# CTRL_MMR0_CTRL_MMR0_IP_CTRL_MMRS_09180000h register map
Vendor: Texas Instruments
Peripheral module from a debugger description file (folder am62L).
Registers are 32-bit, read-write, reset 0x0 unless marked. A register's access mark holds for its fields unless they carry their own. Offsets are as the file gives them; lines under a group give offsets from that group; [hi:lo] are bit positions; {n}, {i} and the like mark numbered series; 'fields as' and 'values as' point back to an identical list; <NAME> marks a mode.

## CTRL_MMR0_IP_CTRL_MMRS
{0xB000+0x1000*i} CTRL_MMR0_IP_CTRL_MMRS_EMMC{i}_CTRL (i=0..2) — Controls drive strength of MMC{i} SDIO mode pins
  [0] EMMC{i}_CTRL_EMMCSD_IO_CLKLB_SEL — Selects IO Pad Loopback for the MMC{i} ModuleField values (others are reserved):1'b0 - Loopback from Unbonded Pad MMCSD{i}_CLKLB1'b1 - Loopback from IO Pin MMCSD{i}_CLK Reset Source: mod_g_rst_n
{0xB004+0x1000*i} CTRL_MMR0_IP_CTRL_MMRS_EMMC{i}_STAT ro (i=0..2) — For determining state of MMCSD 1.8V Signalling
  [0] EMMC{i}_STAT_SIG1P8_EN — Status of 1.8V Signal Activate from MMC{i} ModuleField values (others are reserved):1'b0 - DISABLE_1P8V_SIGNALLING1'b1 - ENABLE_1P8V_SIGNALLING Reset Source: mod_g_rst_n
0x11000 CTRL_MMR0_IP_CTRL_MMRS_OSPI0_CTRL — Controls the OSPI0 loopback clock source
  [4] OSPI0_CTRL_LOOPCLK_SEL — OBSPI0 Loopback clock sourceField values (others are reserved):1'b0 - EXTERNAL_LOOPBACK1'b1 - INTERNAL_LOOPBACK Reset Source: mod_g_rst_n
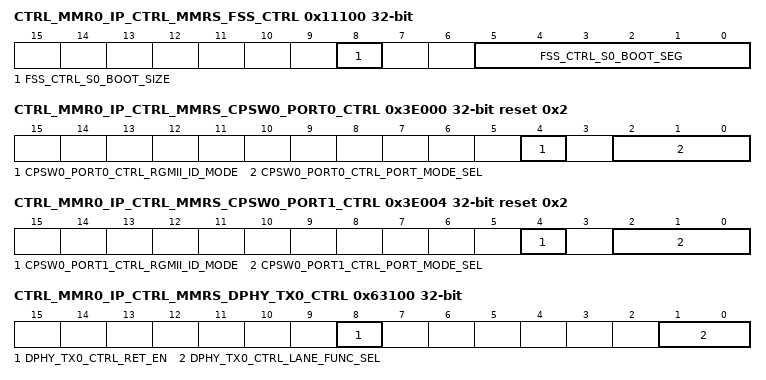
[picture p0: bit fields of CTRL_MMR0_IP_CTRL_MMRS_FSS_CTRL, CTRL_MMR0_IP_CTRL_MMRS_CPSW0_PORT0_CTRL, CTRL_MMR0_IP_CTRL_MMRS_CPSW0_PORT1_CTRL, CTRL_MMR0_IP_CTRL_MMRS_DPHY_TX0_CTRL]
0x11100 CTRL_MMR0_IP_CTRL_MMRS_FSS_CTRL — Controls Flash boot region size and placement
  [8] FSS_CTRL_S0_BOOT_SIZE — Selects the size of the boot block to be used for the S0 (OSPI0) flash interfaceField values (others are reserved):1'b0 - S0_BOOT_SIZE_64MB1'b1 - S0_BOOT_SIZE_128MB Reset Source: mod_g_rst_n
  [5:0] FSS_CTRL_S0_BOOT_SEG — Selects the boot block to be used for the S0 (OSPI0) flash interface. If the s0_boot_size is 128 MB then only bits [4:0] of this field are used. Care must be taken to account for the address translation as to not fall off or wrap the address of the flash. (e.g. if both ECC and authentication are activated for 64 MB boot, the highest valid block number is is 49, as sector 50 is only .2M Bytes in size.) Field values (others are reserved):6'h00 - BLOCK_06'h01 - BLOCK_16'h02 - BLOCK_26'h03 - BLOCK_36'h04 - BLOCK_46'h05 - BLOCK_56'h06 - BLOCK_66'h07 - BLOCK_76'h08 - BLOCK_86'h09 - BLOCK_96'h0A - BLOCK_106'h0B - BLOCK_116'h0C - BLOCK_126'h0D - BLOCK_136'h0E - BLOCK_146'h0F - BLOCK_156'h10 - BLOCK_166'h11 - BLOCK_176'h12 - BLOCK_186'h13 - BLOCK_196'h14 - BLOCK_206'h15 - BLOCK_216'h16 - BLOCK_226'h17 - BLOCK_236'h18 - BLOCK_246'h19 - BLOCK_256'h1A - BLOCK_266'h1B - BLOCK_276'h1C - BLOCK_286'h1D - BLOCK_296'h1E - BLOCK_306'h1F - BLOCK_316'h20 - BLOCK_326'h21 - BLOCK_336'h22 - BLOCK_346'h23 - BLOCK_356'h24 - BLOCK_366'h25 - BLOCK_376'h26 - BLOCK_386'h27 - BLOCK_396'h28 - BLOCK_406'h29 - BLOCK_416'h2A - BLOCK_426'h2B - BLOCK_436'h2C - BLOCK_446'h2D - BLOCK_456'h2E - BLOCK_466'h2F - BLOCK_476'h30 - BLOCK_486'h31 - BLOCK_496'h32 - BLOCK_506'h33 - BLOCK_516'h34 - BLOCK_526'h35 - BLOCK_536'h36 - BLOCK_546'h37 - BLOCK_556'h38 - BLOCK_566'h39 - BLOCK_576'h3A - BLOCK_586'h3B - BLOCK_596'h3C - BLOCK_606'h3D - BLOCK_616'h3E - BLOCK_626'h3F - BLOCK_63 Reset Source: mod_g_rst_n
0x16000 CTRL_MMR0_IP_CTRL_MMRS_TIMER1_CTRL — Controls TIMER1 operation
  [8] TIMER1_CTRL_CASCADE_EN — Activates cascading of TIMER1 to TIMER0Field values (others are reserved):1'b0 - CASCADE_DEACTIVATED1'b1 - CASCADE_ACTIVATED Reset Source: sys_por_rst_n
0x18000 CTRL_MMR0_IP_CTRL_MMRS_TIMER3_CTRL — Controls TIMER3 operation
  [8] TIMER3_CTRL_CASCADE_EN — Activates cascading of TIMER3 to TIMER2Field values (others are reserved):1'b0 - CASCADE_DEACTIVATED1'b1 - CASCADE_ACTIVATED Reset Source: sys_por_rst_n
0x38000 CTRL_MMR0_IP_CTRL_MMRS_I2C2_CTRL — Controls I2C2 operation for open drain I/Os
  [0] I2C2_CTRL_HS_MCS_EN — HS Mode controller current source activate.When set, activates the current-source pull-up on the SCL output. Only one controller on the I2C bus should activate SCL current sourcing. Field values (others are reserved):1'b0 - DISABLE_ACTIVE_PULL1'b1 - ENABLE_ACTIVE_PULL Reset Source: mod_g_rst_n
0x3E000 CTRL_MMR0_IP_CTRL_MMRS_CPSW0_PORT0_CTRL reset 0x2 — Controls Port0 operation of Ethernet Switch CPSW0
  [4] CPSW0_PORT0_CTRL_RGMII_ID_MODE — Port0 RGMII internal transmit delay selectionField values (others are reserved):1'b0 - INT_DELAY1'b1 - NO_DELAY Reset Source: sys_por_rst_n
  [2:0] CPSW0_PORT0_CTRL_PORT_MODE_SEL — Selects Ethernet switch 0 Port0 interface Field values (others are reserved):undefined - undefined3'b001 - RMII3'b010 - RGMII Reset Source: sys_por_rst_n
0x3E004 CTRL_MMR0_IP_CTRL_MMRS_CPSW0_PORT1_CTRL reset 0x2 — Controls Port1 operation of Ethernet Switch CPSW0
  [4] CPSW0_PORT1_CTRL_RGMII_ID_MODE — Port1 RGMII internal transmit delay selectionField values (others are reserved):1'b0 - INT_DELAY1'b1 - NO_DELAY Reset Source: sys_por_rst_n
  [2:0] CPSW0_PORT1_CTRL_PORT_MODE_SEL — Selects Ethernet switch 0 Port1 interface Field values (others are reserved):undefined - undefined3'b001 - RMII3'b010 - RGMII Reset Source: sys_por_rst_n
0x63100 CTRL_MMR0_IP_CTRL_MMRS_DPHY_TX0_CTRL — Controls DPHY_TX0 Lane 0 operation
  [8] DPHY_TX0_CTRL_RET_EN — Retention activate Reset Source: sys_por_rst_n
  [1:0] DPHY_TX0_CTRL_LANE_FUNC_SEL — Selects the source for the 4 lanes of DPHY_TX 0 Field values (others are reserved):2'b00 - DSI0 PPI0 Reset Source: sys_por_rst_n
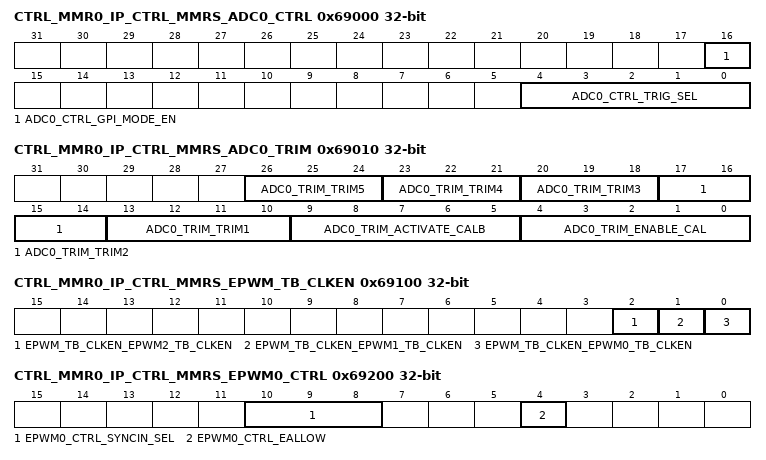
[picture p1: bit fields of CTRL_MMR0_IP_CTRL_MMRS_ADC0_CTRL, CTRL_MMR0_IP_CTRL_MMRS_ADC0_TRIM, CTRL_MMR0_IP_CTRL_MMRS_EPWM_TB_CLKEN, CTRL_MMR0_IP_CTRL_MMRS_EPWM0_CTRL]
0x69000 CTRL_MMR0_IP_CTRL_MMRS_ADC0_CTRL — Controls operation of ADC0
  [16] ADC0_CTRL_GPI_MODE_EN — Activates ADC0 data pins to be used as general purpose inputs when set. This signal is tied to the en_dig_test input of ADC0Field values (others are reserved):1'b0 - ADC in Normal Mode1'b1 - ADC in GPI Mode Reset Source: mod_g_rst_n
  [4:0] ADC0_CTRL_TRIG_SEL — Selects the source of the ADC hardware event triggerField values (others are reserved):5'b00000 - ADC_EXT_TRIGGER0 (Pin)5'b00001 - ADC_EXT_TRIGGER1 (Pin)5'b00010 - EPWM SOCA_OUT5'b00011 - EPWM SOCB_OUTundefined - undefinedundefined - undefinedundefined - undefinedundefined - undefined5'b01000 - TIMER0 PWM 5'b01001 - TIMER1 PWM 5'b01010 - TIMER2 PWM 5'b01011 - TIMER3 PWM Reset Source: mod_g_rst_n
0x69010 CTRL_MMR0_IP_CTRL_MMRS_ADC0_TRIM — Trims Nonlinearity from ADC0
  [26:24] ADC0_TRIM_TRIM5 — Trims Nonlinearities from ADC Reset Source: mod_por_rst_n
  [23:21] ADC0_TRIM_TRIM4 — Trims Nonlinearities from ADC Reset Source: mod_por_rst_n
  [20:18] ADC0_TRIM_TRIM3 — Trims Nonlinearities from ADC Reset Source: mod_por_rst_n
  [17:14] ADC0_TRIM_TRIM2 — Trims Nonlinearities from ADC Reset Source: mod_por_rst_n
  [13:10] ADC0_TRIM_TRIM1 — Trims Nonlinearities from ADC Reset Source: mod_por_rst_n
  [9:5] ADC0_TRIM_ACTIVATE_CALB — Trims Nonlinearities from ADC Reset Source: mod_por_rst_n
  [4:0] ADC0_TRIM_ENABLE_CAL — Trims Nonlinearities from ADC Reset Source: mod_por_rst_n
0x69100 CTRL_MMR0_IP_CTRL_MMRS_EPWM_TB_CLKEN — Controls Timebase Counter of EPWM Modules
  [2] EPWM_TB_CLKEN_EPWM2_TB_CLKEN — Activates Timebase Clock of EPWM2 When SetField values (others are reserved):1'b0 - DEACTIVATE1'b1 - ACTIVATE Reset Source: mod_g_rst_n
  [1] EPWM_TB_CLKEN_EPWM1_TB_CLKEN — Activates Timebase Clock of EPWM1 When SetField values (others are reserved):1'b0 - DEACTIVATE1'b1 - ACTIVATE Reset Source: mod_g_rst_n
  [0] EPWM_TB_CLKEN_EPWM0_TB_CLKEN — Activates Timebase Clock of EPWM0 When SetField values (others are reserved):1'b0 - DEACTIVATE1'b1 - ACTIVATE Reset Source: mod_g_rst_n
0x69200 CTRL_MMR0_IP_CTRL_MMRS_EPWM0_CTRL — Controls EPWM0 Operation
  [10:8] EPWM0_CTRL_SYNCIN_SEL — Selects the source of the EPWM0 synchronization inputField values (others are reserved):3'b000 - EPWM0_SYNCIN (Pin)undefined - undefined3'b010 - Time Sync Router 193'b011 - CPSW0 CMP Event Reset Source: mod_g_rst_n
  [4] EPWM0_CTRL_EALLOW — Activate write access to EPWM tripzone registers Reset Source: mod_g_rst_n
0x69210 CTRL_MMR0_IP_CTRL_MMRS_EPWM1_CTRL — Controls EPWM1 Operation
  [4] EPWM1_CTRL_EALLOW — Activate write access to EPWM tripzone registers Reset Source: mod_g_rst_n
0x69220 CTRL_MMR0_IP_CTRL_MMRS_EPWM2_CTRL — Controls EPWM2 Operation
  [4] EPWM2_CTRL_EALLOW — Activate write access to EPWM tripzone registers Reset Source: mod_g_rst_n
{0x69300+4i} CTRL_MMR0_IP_CTRL_MMRS_EQEP{i}_CTRL (i=0..2) — Selects Start of Conversion A input signal for EQEP{i}. This can be used to create a strobe (EQEP{i}_S) from one of the on chip sources selected by the EQEP{i} SOCA mux.
  [4:0] EQEP{i}_CTRL_SOCA_SEL — Selects the source of SOCA input for EQEP{i}Field values (others are reserved):5'b00000 - ADC_EXT_TRIGGER0 (Pin)5'b00001 - ADC_EXT_TRIGGER1 (Pin)5'b00010 - EPWM SOCA_OUT5'b00011 - EPWM SOCB_OUTundefined - undefinedundefined - undefinedundefined - undefinedundefined - undefined5'b01000 - TIMER0 PWM 5'b01001 - TIMER1 PWM 5'b01010 - TIMER2 PWM 5'b01011 - TIMER3 PWM undefined - undefinedundefined - undefinedundefined - undefinedundefined - undefined5'b10000 - WKUP TIMER0 PWM undefined - undefined5'b10001 - WKUP TIMER1 PWM Reset Source: mod_g_rst_n
